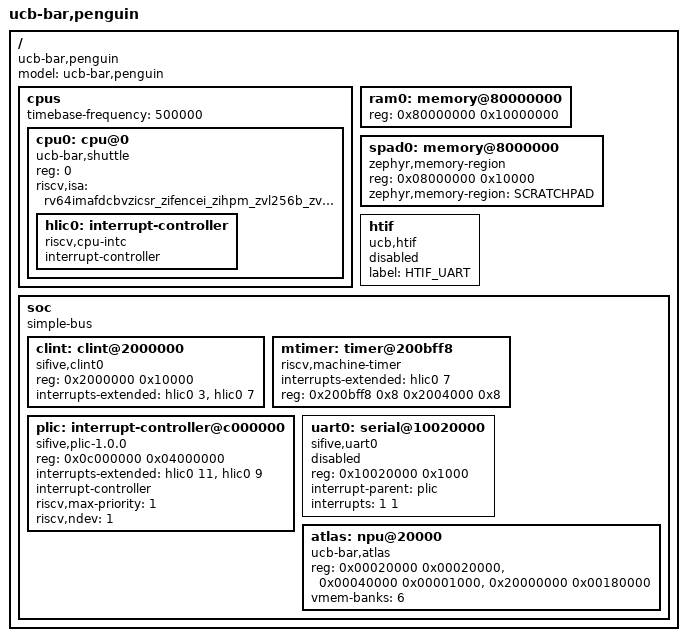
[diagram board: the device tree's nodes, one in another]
/*
 * Chipyard "penguin" SoC: Shuttle + Saturn RVV.
 *
 * SPDX-License-Identifier: Apache-2.0
 *
 * Sources: the course's tapeout repo, T/ = $TAPEOUT_CHIPYARD (HEAD 48c3a7d1); RC/ =
 * T/generators/rocket-chip/src/main/scala. The taped-out config is
 * EE290TapeoutConfig (T/README.md:69-83, T/generators/chipyard/src/main/scala/
 * config/EE290Configs.scala:12-19). Tags: [R] read in source, [I] inferred.
 *
 * Still open: a DTS elaborated for EE290TapeoutConfig does not exist anywhere
 * readable. The real one is embedded in the BootROM: dump 64 KiB at 0x10000 on
 * silicon and `dtc -I dtb` it (testchipip bootrom.S:63-64, a1 = &_dtb).
 */

/dts-v1/;

/ {
	#address-cells = <1>;
	#size-cells = <1>;
	compatible = "ucb-bar,penguin";
	model = "ucb-bar,penguin";

	cpus {
		#address-cells = <1>;
		#size-cells = <0>;
		/* mtime rate, 500 kHz: WithPeripheryBusFrequency(500) ->
		 * WithTimebase(500e3) (ClockingFragments.scala:91-96, H).
		 * CAVEAT [R] (RC/subsystem/RTC.scala:17-31): mtime is divided
		 * down from the real CBUS clock by a STATIC divider of
		 * 500 MHz / 500 kHz = 1000, so mtime = f_CBUS / 1000. It is
		 * 500 kHz only if the uncore clock pin really runs at 500 MHz
		 * (125 MHz -> 125 kHz, 50 MHz -> 50 kHz). Measure with
		 * samples/hw_probe. Zephyr takes the rate from
		 * CONFIG_SYS_CLOCK_HW_CYCLES_PER_SEC, which must equal this.
		 */
		timebase-frequency = <500000>;

		/* One Shuttle hart, hartid 0: WithNShuttleCores(1)
		 * (chipyard AtlasConfigs.scala:33,44; shuttle Configs.scala:14-37),
		 * confidence H; Atlas is a TL peripheral, not a hart.
		 * For more harts add cpu@N + hlicN and extend the PLIC/CLINT/mtimer
		 * interrupts-extended lists.
		 */
		cpu0: cpu@0 {
			device_type = "cpu";
			reg = <0>;
			status = "okay";
			compatible = "ucb-bar,shuttle", "riscv";
			/* Exact string rocket-chip's generator emits for Shuttle
			 * + Saturn (RC/tile/BaseTile.scala:106-145, parameters as
			 * from the tapeout repo): no "_" between "v" and "zicsr",
			 * no zicntr (commented out in the generator: rdtime is
			 * not implemented), zihpm listed although
			 * nPerfCounters = 0. [R] generator / [I] parameter values.
			 * DT consumers only: this is NOT a valid GCC -march;
			 * Zephyr's -march comes from the selects in
			 * soc/chipyard/penguin/Kconfig and is deliberately
			 * unchanged. The hart also has S and U modes and Sv39
			 * (mmu-type riscv,sv39; RC/tile/Core.scala:64), but Zephyr
			 * runs in M-mode; the Zephyr riscv,cpus binding has no
			 * mmu-type use, so it is not added.
			 */
			riscv,isa = "rv64imafdcbvzicsr_zifencei_zihpm_zvl256b_zve64d_zvfh_zfh_zba_zbb_zbs_zvbb_zvfofp8min_zfbfmin_zvfbfmin_zvfbfa";

			hlic0: interrupt-controller {
				compatible = "riscv,cpu-intc";
				#address-cells = <0>;
				#interrupt-cells = <1>;
				interrupt-controller;
			};
		};
	};

	/* DRAM base 0x80000000 (BootAddrReg default 0x80000000, [R]
	 * testchipip BootAddrReg.scala:13). DRAM is cacheable and coherent via
	 * the TileLink broadcast hub (UNCACHED -> TRACKED, RC/tilelink/
	 * Broadcast.scala:54-75); the 0x4000_0000 (1 GiB) and 0x8_8000_0000
	 * (30 GiB) SerialTL windows are uncached. Size is OUR choice, not a hardware fact:
	 * the sim config maps 64 GiB (WithExtMemSize(0x10_0000_0000),
	 * AtlasConfigs.scala:148, H), the tapeout chip has no DRAM port and sees
	 * a 32 GiB window (l.59-62), the FPGA host gives 16 GiB (l.123).
	 * Zephyr only needs what it links, so 256 MiB fits `#address-cells = <1>`
	 * (a cell pair would be needed only to describe the >4 GiB uncached
	 * windows at 0x8_8000_0000, which this board port does not use).
	 *
	 * Atlas test buffers: upstream host tests keep Atlas DRAM data at
	 * ATLAS_DRAM_BASE = 0x9000_0000 (T/tests/atlas_mmio.h:22-26), which is
	 * exactly the END of this 256 MiB node. Keep Atlas buffers at or above
	 * 0x9000_0000 and never let the linker/heap grow into them.
	 */
	ram0: memory@80000000 {
		device_type = "memory";
		reg = <0x80000000 0x10000000>;
	};

	/* 64 KiB scratchpad on the MBUS at 0x0800_0000
	 * (chipyard AbstractConfig.scala:120-121, H; inherited by EE290SimConfig
	 * through AbstractConfig). Exposed as a Zephyr linker region
	 * "SCRATCHPAD" region. Spike does not model it, so code
	 * touching it faults on Spike; it exists for the linker and for silicon/
	 * RTL sim. Coherence with Atlas DMA/Saturn is unknown.
	 */
	spad0: memory@8000000 {
		compatible = "zephyr,memory-region", "mmio-sram";
		reg = <0x08000000 0x10000>;
		zephyr,memory-region = "SCRATCHPAD";
	};

	htif: htif {
		compatible = "ucb,htif";
		label = "HTIF_UART";
		status = "disabled";
	};

	soc {
		#address-cells = <1>;
		#size-cells = <1>;
		compatible = "simple-bus";
		ranges;

		/* CLINT 0x0200_0000, 64 KiB, on CBUS [R] (RC/devices/tilelink/
		 * CLINT.scala:25,31-33,84-101): msip hart h at 4*h (bit 0 only),
		 * mtimecmp hart h at 0x4000 + 8*h, mtime at 0xBFF8 (hi words +4).
		 * mtime resets to 0 and counts rtcTick only (see the timebase
		 * caveat above). mtimecmp has NO reset value (CLINT.scala:75):
		 * on silicon it powers up random and MTIP (mtime >= mtimecmp)
		 * may be spuriously asserted until software writes it. Zephyr is
		 * safe: riscv_machine_timer's PRE_KERNEL_2 init writes mtimecmp
		 * before irq_enable(), and mie.MTIE is not set earlier (the
		 * BootROM enables only MSIP, bootrom.S:34-36). Anything that
		 * enables MTIE earlier must write mtimecmp first.
		 */
		clint: clint@2000000 {
			compatible = "sifive,clint0";
			reg = <0x2000000 0x10000>;
			interrupts-extended = <&hlic0 3 &hlic0 7>;
		};

		mtimer: timer@200bff8 {
			compatible = "riscv,machine-timer";
			interrupts-extended = <&hlic0 7>;
			reg = <0x200bff8 0x8 0x2004000 0x8>;
			reg-names = "mtime", "mtimecmp";
		};

		/* PLIC 0x0C00_0000, 64 MiB window [R] (RC/devices/tilelink/
		 * Plic.scala:49-68). ndev = number of sources = 1 (UART only:
		 * WithNExtTopInterrupts(0), no other interrupt device); the
		 * max priority is min(7, ndev) rounded up to a bit mask = 1
		 * (Plic.scala:68,113-115), so priority and threshold registers
		 * are ONE bit wide: a priority above 1 is stored as 0 and
		 * DISABLES the source. Zephyr's riscv_plic_set_priority()
		 * clamps to riscv,max-priority, so use priority 1 only.
		 * Contexts: ctx 0 = M, ctx 1 = S (the interrupts-extended order).
		 * The TileLink gateway is level-triggered.
		 *
		 * Zephyr driver caveat (intc_plic.c): nr_irqs = MIN(ndev,
		 * MAX_IRQ_PER_AGGREGATOR) and the ISR rejects local_irq >=
		 * nr_irqs, i.e. the driver treats ndev as a count INCLUDING
		 * source 0. With the true ndev = 1, source 1 (the UART) is
		 * rejected as spurious in the ISR. Console is polled/HTIF, so
		 * nothing uses UART IRQs today; to use them set ndev = <2>
		 * (harmless: absent sources read 0, undefZero) or fix the driver.
		 * (Upstream fix: the PLIC driver note in README.md, Known issues.)
		 */
		plic: interrupt-controller@c000000 {
			compatible = "sifive,plic-1.0.0";
			reg = <0x0c000000 0x04000000>;
			interrupts-extended = <&hlic0 11 &hlic0 9>;
			interrupt-controller;
			#address-cells = <0>;
			#interrupt-cells = <2>;
			riscv,max-priority = <1>;
			riscv,ndev = <1>;	/* keep in sync with the IRQ Kconfig in soc/.../Kconfig.defconfig */
		};

		/* UART0 0x1002_0000, sifive,uart0, PBUS, 115200 baud init
		 * (PeripheralFragments.scala:69 WithUART), PLIC source 1 [R]
		 * (UART.scala:122,299-303; the only PLIC input). Reset divisor
		 * is PBUS_freq / 115200 = 4340 for 500 MHz; txen/rxen reset to
		 * 0. The priority cell is 1: the PLIC priority is 1 bit wide.
		 */
		uart0: serial@10020000 {
			compatible = "sifive,uart0";
			reg = <0x10020000 0x1000>;
			reg-names = "control";
			interrupt-parent = <&plic>;
			interrupts = <1 1>;	/* source 1, priority 1 (max) */
			status = "disabled";
		};

		/* Other taped-out devices with no Zephyr binding, so not
		 * described as nodes (a node with no binding adds nothing but
		 * risk); all [R] unless noted, addresses are on CBUS/PBUS:
		 *   debug module     0x0000_0000 4 KiB (sifive,debug-013, JTAG DTM,
		 *                    SBA 64-bit; RC/devices/debug/Debug.scala:112,142)
		 *   boot-address-reg 0x0000_1000 4 KiB (resets to 0x8000_0000)
		 *   error device     0x0000_3000 4 KiB (sifive,error0)
		 *   BootROM          0x0001_0000 64 KiB (holds the real DTB)
		 *   clock-gater      0x0010_0000 (reset value 1 = tile clock on;
		 *                    tile reg probably at +0x4 [I])
		 *   tile-reset-setter 0x0011_0000 (reset 0 = tile not held in reset)
		 *   Tacit trace enc. 0x0300_0000 64 KiB, trace-sink DMA regs
		 *                    0x0301_0000 4 KiB (the Tacit trace encoder IS
		 *                    in the taped-out EE290TapeoutConfig)
		 * Do not touch them from Zephyr unless you are gating the tile.
		 */

		/* Atlas NPU: a TileLink peripheral, not a hart; Chipyard emits no
		 * DTS node for it, so this one is hand-written. Windows are
		 * AtlasMemMap in bringup-chipyard/generators/atlas-npu/src/main/
		 * scala/atlas/scalar/ScalarCore.scala:39-51 (R): imem 0x20000
		 * 128 KiB and csr 0x40000 (4 KiB window, 7 words) on the PBUS,
		 * vmem 0x2000_0000 1.5 MiB (6 x 256 KiB banks) on the SBUS. No
		 * interrupt: the RTL has no IRQ output. Unit address is the
		 * first reg (imem). The csr window starts exactly where imem
		 * ends; that is adjacent, not overlapping.
		 */
		atlas: npu@20000 {
			compatible = "ucb-bar,atlas";
			reg = <0x00020000 0x00020000>,
			      <0x00040000 0x00001000>,
			      <0x20000000 0x00180000>;
			reg-names = "imem", "csr", "vmem";
			vmem-banks = <6>;
			status = "okay";
		};
	};
};
